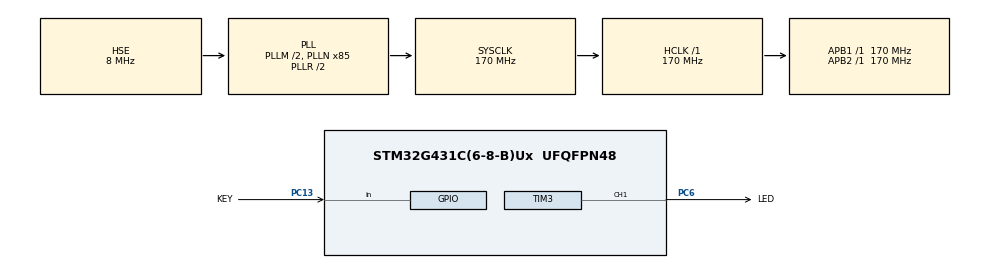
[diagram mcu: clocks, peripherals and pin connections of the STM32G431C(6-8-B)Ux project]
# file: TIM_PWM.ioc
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Mcu.Family=STM32G4
Mcu.Name=STM32G431C(6-8-B)Ux
Mcu.Package=UFQFPN48
NVIC.PriorityGroup=NVIC_PRIORITYGROUP_4
PA13.Mode=Serial_Wire
PA13.Signal=SYS_JTMS-SWDIO
PA14.Mode=Serial_Wire
PA14.Signal=SYS_JTCK-SWCLK
PC13.GPIO_Label=KEY
PC13.GPIO_PuPd=GPIO_PULLDOWN
PC13.Signal=GPIO_Input
PC6.GPIO_Label=LED
PC6.Signal=S_TIM3_CH1
PF0-OSC_IN.Mode=HSE-External-Oscillator
PF0-OSC_IN.Signal=RCC_OSC_IN
PF1-OSC_OUT.Mode=HSE-External-Oscillator
PF1-OSC_OUT.Signal=RCC_OSC_OUT
ProjectManager.HeapSize=0x200
ProjectManager.StackSize=0x400
ProjectManager.TargetToolchain=STM32CubeIDE
RCC.ADC12Freq_Value=170000000
RCC.AHBFreq_Value=170000000
RCC.APB1Freq_Value=170000000
RCC.APB1TimFreq_Value=170000000
RCC.APB2Freq_Value=170000000
RCC.APB2TimFreq_Value=170000000
RCC.CortexFreq_Value=170000000
RCC.EXTERNAL_CLOCK_VALUE=12288000
RCC.HCLKFreq_Value=170000000
RCC.HSE_VALUE=8000000
RCC.HSI48_VALUE=48000000
RCC.HSI_VALUE=16000000
RCC.LSE_VALUE=32768
RCC.PLLM=RCC_PLLM_DIV2
RCC.PLLN=85
RCC.PLLSourceVirtual=RCC_PLLSOURCE_HSE
RCC.SYSCLKFreq_VALUE=170000000
RCC.SYSCLKSource=RCC_SYSCLKSOURCE_PLLCLK
RCC.USBFreq_Value=170000000
RCC.VCOOutputFreq_Value=340000000
SH.S_TIM3_CH1.0=TIM3_CH1,PWM Generation1 CH1
TIM3.Channel-PWM\ Generation1\ CH1=TIM_CHANNEL_1
TIM3.PeriodNoDither=10000
TIM3.Prescaler=17
VP_SYS_VS_DBSignals.Mode=DisableDeadBatterySignals
board=custom

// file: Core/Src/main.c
/* USER CODE BEGIN Header */
/**
  ******************************************************************************
  * @file           : main.c
  * @brief          : Main program body
  ******************************************************************************
  * @attention
  *
  * Copyright (c) 2025 STMicroelectronics.
  * All rights reserved.
  *
  * This software is licensed under terms that can be found in the LICENSE file
  * in the root directory of this software component.
  * If no LICENSE file comes with this software, it is provided AS-IS.
  *
  ******************************************************************************
  */
/* USER CODE END Header */
#include "main.h"

/* USER CODE BEGIN PD */

#define PWM_INC	20

/* USER CODE END PD */

TIM_HandleTypeDef htim3;

void SystemClock_Config(void);
static void MX_GPIO_Init(void);
static void MX_TIM3_Init(void);

/* USER CODE BEGIN 0 */

void SetPWM(uint32_t pwm_value) {
	TIM3->CCR1 = pwm_value;
}

/* USER CODE END 0 */

int main(void)
{

  /* USER CODE BEGIN 1 */
	int16_t PWM_Value = 0;
	int16_t PWM_Value_Inc = PWM_INC;
  /* USER CODE END 1 */

  /* MCU Configuration--------------------------------------------------------*/

  /* Reset of all peripherals, Initializes the Flash interface and the Systick. */
  HAL_Init();

  /* Configure the system clock */
  SystemClock_Config();

  /* Initialize all configured peripherals */
  MX_GPIO_Init();
  MX_TIM3_Init();
  /* USER CODE BEGIN 2 */

  HAL_TIM_PWM_Start(&htim3, TIM_CHANNEL_1);
  SetPWM(0);

  /* USER CODE END 2 */

  /* Infinite loop */
  /* USER CODE BEGIN WHILE */
  while (1)
  {
	  // Set PWM
	  SetPWM((uint32_t) PWM_Value);

	  PWM_Value = PWM_Value + PWM_Value_Inc;

	  if (PWM_Value > htim3.Init.Period-1) {
		  PWM_Value_Inc = -PWM_INC;
	  }

	  if (PWM_Value < 1) {
		  PWM_Value_Inc = PWM_INC;
	  }

	  HAL_Delay(1);
    /* USER CODE END WHILE */

  }
}

void SystemClock_Config(void)
{
  RCC_OscInitTypeDef RCC_OscInitStruct = {0};
  RCC_ClkInitTypeDef RCC_ClkInitStruct = {0};

  /** Configure the main internal regulator output voltage
  */
  HAL_PWREx_ControlVoltageScaling(PWR_REGULATOR_VOLTAGE_SCALE1_BOOST);

  /** Initializes the RCC Oscillators according to the specified parameters
  * in the RCC_OscInitTypeDef structure.
  */
  RCC_OscInitStruct.OscillatorType = RCC_OSCILLATORTYPE_HSE;
  RCC_OscInitStruct.HSEState = RCC_HSE_ON;
  RCC_OscInitStruct.PLL.PLLState = RCC_PLL_ON;
  RCC_OscInitStruct.PLL.PLLSource = RCC_PLLSOURCE_HSE;
  RCC_OscInitStruct.PLL.PLLM = RCC_PLLM_DIV2;
  RCC_OscInitStruct.PLL.PLLN = 85;
  RCC_OscInitStruct.PLL.PLLP = RCC_PLLP_DIV2;
  RCC_OscInitStruct.PLL.PLLQ = RCC_PLLQ_DIV2;
  RCC_OscInitStruct.PLL.PLLR = RCC_PLLR_DIV2;
  if (HAL_RCC_OscConfig(&RCC_OscInitStruct) != HAL_OK)
  {
    Error_Handler();
  }

  /** Initializes the CPU, AHB and APB buses clocks
  */
  RCC_ClkInitStruct.ClockType = RCC_CLOCKTYPE_HCLK|RCC_CLOCKTYPE_SYSCLK
                              |RCC_CLOCKTYPE_PCLK1|RCC_CLOCKTYPE_PCLK2;
  RCC_ClkInitStruct.SYSCLKSource = RCC_SYSCLKSOURCE_PLLCLK;
  RCC_ClkInitStruct.AHBCLKDivider = RCC_SYSCLK_DIV1;
  RCC_ClkInitStruct.APB1CLKDivider = RCC_HCLK_DIV1;
  RCC_ClkInitStruct.APB2CLKDivider = RCC_HCLK_DIV1;

  if (HAL_RCC_ClockConfig(&RCC_ClkInitStruct, FLASH_LATENCY_4) != HAL_OK)
  {
    Error_Handler();
  }
}

static void MX_TIM3_Init(void)
{

  TIM_MasterConfigTypeDef sMasterConfig = {0};
  TIM_OC_InitTypeDef sConfigOC = {0};

  htim3.Instance = TIM3;
  htim3.Init.Prescaler = 17;
  htim3.Init.CounterMode = TIM_COUNTERMODE_UP;
  htim3.Init.Period = 10000;
  htim3.Init.ClockDivision = TIM_CLOCKDIVISION_DIV1;
  htim3.Init.AutoReloadPreload = TIM_AUTORELOAD_PRELOAD_DISABLE;
  if (HAL_TIM_PWM_Init(&htim3) != HAL_OK)
  {
    Error_Handler();
  }
  sMasterConfig.MasterOutputTrigger = TIM_TRGO_RESET;
  sMasterConfig.MasterSlaveMode = TIM_MASTERSLAVEMODE_DISABLE;
  if (HAL_TIMEx_MasterConfigSynchronization(&htim3, &sMasterConfig) != HAL_OK)
  {
    Error_Handler();
  }
  sConfigOC.OCMode = TIM_OCMODE_PWM1;
  sConfigOC.Pulse = 0;
  sConfigOC.OCPolarity = TIM_OCPOLARITY_HIGH;
  sConfigOC.OCFastMode = TIM_OCFAST_DISABLE;
  if (HAL_TIM_PWM_ConfigChannel(&htim3, &sConfigOC, TIM_CHANNEL_1) != HAL_OK)
  {
    Error_Handler();
  }
  HAL_TIM_MspPostInit(&htim3);

}

static void MX_GPIO_Init(void)
{
  GPIO_InitTypeDef GPIO_InitStruct = {0};

  /* GPIO Ports Clock Enable */
  __HAL_RCC_GPIOC_CLK_ENABLE();
  __HAL_RCC_GPIOF_CLK_ENABLE();
  __HAL_RCC_GPIOA_CLK_ENABLE();

  /*Configure GPIO pin : KEY_Pin */
  GPIO_InitStruct.Pin = KEY_Pin;
  GPIO_InitStruct.Mode = GPIO_MODE_INPUT;
  GPIO_InitStruct.Pull = GPIO_PULLDOWN;
  HAL_GPIO_Init(KEY_GPIO_Port, &GPIO_InitStruct);

}

void Error_Handler(void)
{
  __disable_irq();
  while (1)
  {
  }
}
